# debugss_DEBUGSS_DEBUG_CELL_ROM_SLV_00073C020000h register map
Vendor: Texas Instruments
Peripheral module from a debugger description file (folder AM275x).
Registers are 32-bit, read-only, reset values left out (the file's numbers can be read two ways) unless marked. A register's access mark holds for its fields unless they carry their own. Offsets are as the file gives them; lines under a group give offsets from that group; [hi:lo] are bit positions; {n}, {i} and the like mark numbered series; 'fields as' and 'values as' point back to an identical list; <NAME> marks a mode.

## debugss_DEBUG_CELL_ROM_SLV
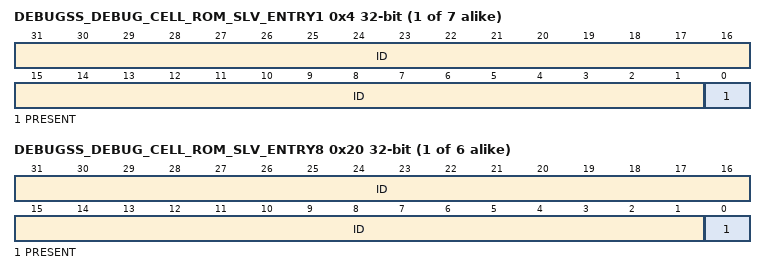
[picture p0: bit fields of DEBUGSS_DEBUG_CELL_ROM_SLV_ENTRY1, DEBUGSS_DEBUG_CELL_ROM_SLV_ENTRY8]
{0x0+4i} DEBUGSS_DEBUG_CELL_ROM_SLV_ENTRY{i} (i=1..7)
  [31:1] ID — 4kB - MSMCv3 CSCTI Instance {i} Reset Source: dbg_srst_mod_g_rst_n
  [0] PRESENT — Component present,1, or not present,0, status bit Reset Source: dbg_srst_mod_g_rst_n
{0x0+4i} DEBUGSS_DEBUG_CELL_ROM_SLV_ENTRY{i} (i=8..13)
  [31:1] ID — 256kB - Processor Cluster Instance {i-8} Reset Source: dbg_srst_mod_g_rst_n
  [0] PRESENT — Component present,1, or not present,0, status bit Reset Source: dbg_srst_mod_g_rst_n
0x50 DEBUGSS_DEBUG_CELL_ROM_SLV_ENTRY14
  [31:0] ID — End of table Reset Source: dbg_srst_mod_g_rst_n
{0xFC0+4i} DEBUGSS_DEBUG_CELL_ROM_SLV_PERIPHID{i} (i=4..7)
  [31:0] ID — Peripheral Identification Number Reset Source: dbg_srst_mod_g_rst_n
{0xFE0+4i} DEBUGSS_DEBUG_CELL_ROM_SLV_PERIPHID{i} (i=0..3)
  fields as DEBUGSS_DEBUG_CELL_ROM_SLV_PERIPHID4
{0xFF0+4i} DEBUGSS_DEBUG_CELL_ROM_SLV_COMPONENTID{i} (i=0..3)
  [31:0] ID — Component Identification Number Reset Source: dbg_srst_mod_g_rst_n
